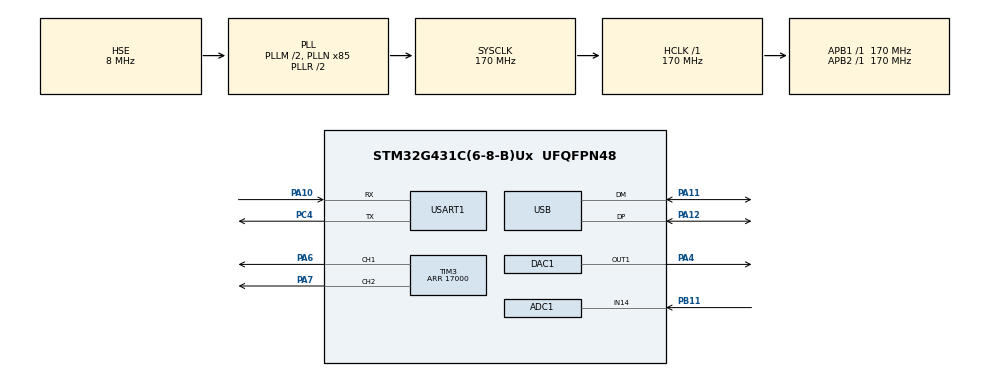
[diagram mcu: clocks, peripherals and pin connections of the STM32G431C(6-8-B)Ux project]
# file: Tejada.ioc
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ADC1.Channel-0\#ChannelRegularConversion=ADC_CHANNEL_14
ADC1.ClockPrescaler=ADC_CLOCK_ASYNC_DIV4
ADC1.DMAContinuousRequests=DISABLE
ADC1.ExternalTrigConv=ADC_EXTERNALTRIG_T8_TRGO
ADC1.NbrOfConversionFlag=1
ADC1.OffsetNumber-0\#ChannelRegularConversion=ADC_OFFSET_NONE
ADC1.Rank-0\#ChannelRegularConversion=1
ADC1.SamplingTime-0\#ChannelRegularConversion=ADC_SAMPLETIME_247CYCLES_5
ADC1.master=1
Mcu.Family=STM32G4
Mcu.Name=STM32G431C(6-8-B)Ux
Mcu.Package=UFQFPN48
NVIC.ADC1_2_IRQn=true\:0\:0\:false\:false\:true\:true\:true\:true
NVIC.PriorityGroup=NVIC_PRIORITYGROUP_4
NVIC.TIM7_IRQn=true\:0\:0\:false\:false\:true\:true\:true\:true
PA10.Mode=Asynchronous
PA10.Signal=USART1_RX
PA11.Mode=Device
PA11.Signal=USB_DM
PA12.Mode=Device
PA12.Signal=USB_DP
PA4.Signal=COMP_DAC11_group
PA6.Signal=S_TIM3_CH1
PA7.Signal=S_TIM3_CH2
PB11.Mode=IN14-Single-Ended
PB11.Signal=ADC1_IN14
PC4.Mode=Asynchronous
PC4.Signal=USART1_TX
PF0-OSC_IN.Mode=HSE-External-Oscillator
PF0-OSC_IN.Signal=RCC_OSC_IN
PF1-OSC_OUT.Mode=HSE-External-Oscillator
PF1-OSC_OUT.Signal=RCC_OSC_OUT
ProjectManager.HeapSize=0x200
ProjectManager.StackSize=0x400
ProjectManager.TargetToolchain=STM32CubeIDE
RCC.ADC12Freq_Value=170000000
RCC.AHBFreq_Value=170000000
RCC.APB1Freq_Value=170000000
RCC.APB1TimFreq_Value=170000000
RCC.APB2Freq_Value=170000000
RCC.APB2TimFreq_Value=170000000
RCC.CK48CLockSelection=RCC_USBCLKSOURCE_HSI48
RCC.CortexFreq_Value=170000000
RCC.EXTERNAL_CLOCK_VALUE=12288000
RCC.HCLKFreq_Value=170000000
RCC.HSE_VALUE=8000000
RCC.HSI48_VALUE=48000000
RCC.HSI_VALUE=16000000
RCC.LSE_VALUE=32768
RCC.PLLM=RCC_PLLM_DIV2
RCC.PLLN=85
RCC.PLLSourceVirtual=RCC_PLLSOURCE_HSE
RCC.SYSCLKFreq_VALUE=170000000
RCC.SYSCLKSource=RCC_SYSCLKSOURCE_PLLCLK
RCC.USBFreq_Value=48000000
RCC.VCOOutputFreq_Value=340000000
SH.COMP_DAC11_group.0=DAC1_OUT1,DAC_OUT1
SH.S_TIM3_CH1.0=TIM3_CH1,PWM Generation1 CH1
SH.S_TIM3_CH2.0=TIM3_CH2,PWM Generation2 CH2
TIM3.AutoReloadPreload=TIM_AUTORELOAD_PRELOAD_ENABLE
TIM3.Channel-PWM\ Generation1\ CH1=TIM_CHANNEL_1
TIM3.Channel-PWM\ Generation2\ CH2=TIM_CHANNEL_2
TIM3.PeriodNoDither=17000
TIM3.PulseNoDither_1=0
TIM7.AutoReloadPreload=TIM_AUTORELOAD_PRELOAD_ENABLE
TIM7.Prescaler=4
TIM8.AutoReloadPreload=TIM_AUTORELOAD_PRELOAD_ENABLE
TIM8.PeriodNoDither=33999
TIM8.TIM_MasterOutputTrigger=TIM_TRGO_UPDATE
USART1.VirtualMode-Asynchronous=VM_ASYNC
VP_SYS_VS_DBSignals.Mode=DisableDeadBatterySignals
VP_TIM3_VS_ClockSourceINT.Mode=Internal
VP_TIM7_VS_ClockSourceINT.Mode=Enable_Timer
VP_TIM8_VS_ClockSourceINT.Mode=Internal
board=custom

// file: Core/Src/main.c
/* USER CODE BEGIN Header */
/**
  ******************************************************************************
  * @file           : main.c
  * @brief          : Main program body
  ******************************************************************************
  * @attention
  *
  * Copyright (c) 2025 STMicroelectronics.
  * All rights reserved.
  *
  * This software is licensed under terms that can be found in the LICENSE file
  * in the root directory of this software component.
  * If no LICENSE file comes with this software, it is provided AS-IS.
  *
  ******************************************************************************
  */
/* USER CODE END Header */
#include "main.h"
#include "adc.h"
#include "dac.h"
#include "tim.h"
#include "usart.h"
#include "usb.h"
#include "gpio.h"

void SystemClock_Config(void);

int main(void)
{

  /* MCU Configuration--------------------------------------------------------*/

  /* Reset of all peripherals, Initializes the Flash interface and the Systick. */
  HAL_Init();

  /* Configure the system clock */
  SystemClock_Config();

  /* Initialize all configured peripherals */
  MX_GPIO_Init();
  MX_ADC1_Init();
  MX_TIM8_Init();
  MX_USB_PCD_Init();
  MX_TIM7_Init();
  MX_DAC1_Init();
  MX_USART1_UART_Init();
  MX_TIM3_Init();
  /* USER CODE BEGIN 2 */
  HAL_DAC_Start(&hdac1,DAC_CHANNEL_1 );
  HAL_DAC_SetValue(&hdac1, DAC_CHANNEL_1,DAC_ALIGN_12B_R, 4030);
  /* USER CODE END 2 */

  /* Infinite loop */
  while (1)
  {

  }
}

void SystemClock_Config(void)
{
  RCC_OscInitTypeDef RCC_OscInitStruct = {0};
  RCC_ClkInitTypeDef RCC_ClkInitStruct = {0};

  /** Configure the main internal regulator output voltage
  */
  HAL_PWREx_ControlVoltageScaling(PWR_REGULATOR_VOLTAGE_SCALE1_BOOST);

  /** Initializes the RCC Oscillators according to the specified parameters
  * in the RCC_OscInitTypeDef structure.
  */
  RCC_OscInitStruct.OscillatorType = RCC_OSCILLATORTYPE_HSI48|RCC_OSCILLATORTYPE_HSE;
  RCC_OscInitStruct.HSEState = RCC_HSE_ON;
  RCC_OscInitStruct.HSI48State = RCC_HSI48_ON;
  RCC_OscInitStruct.PLL.PLLState = RCC_PLL_ON;
  RCC_OscInitStruct.PLL.PLLSource = RCC_PLLSOURCE_HSE;
  RCC_OscInitStruct.PLL.PLLM = RCC_PLLM_DIV2;
  RCC_OscInitStruct.PLL.PLLN = 85;
  RCC_OscInitStruct.PLL.PLLP = RCC_PLLP_DIV2;
  RCC_OscInitStruct.PLL.PLLQ = RCC_PLLQ_DIV2;
  RCC_OscInitStruct.PLL.PLLR = RCC_PLLR_DIV2;
  if (HAL_RCC_OscConfig(&RCC_OscInitStruct) != HAL_OK)
  {
    Error_Handler();
  }

  /** Initializes the CPU, AHB and APB buses clocks
  */
  RCC_ClkInitStruct.ClockType = RCC_CLOCKTYPE_HCLK|RCC_CLOCKTYPE_SYSCLK
                              |RCC_CLOCKTYPE_PCLK1|RCC_CLOCKTYPE_PCLK2;
  RCC_ClkInitStruct.SYSCLKSource = RCC_SYSCLKSOURCE_PLLCLK;
  RCC_ClkInitStruct.AHBCLKDivider = RCC_SYSCLK_DIV1;
  RCC_ClkInitStruct.APB1CLKDivider = RCC_HCLK_DIV1;
  RCC_ClkInitStruct.APB2CLKDivider = RCC_HCLK_DIV1;

  if (HAL_RCC_ClockConfig(&RCC_ClkInitStruct, FLASH_LATENCY_4) != HAL_OK)
  {
    Error_Handler();
  }
}

void Error_Handler(void)
{
  __disable_irq();
  while (1)
  {
  }
}
